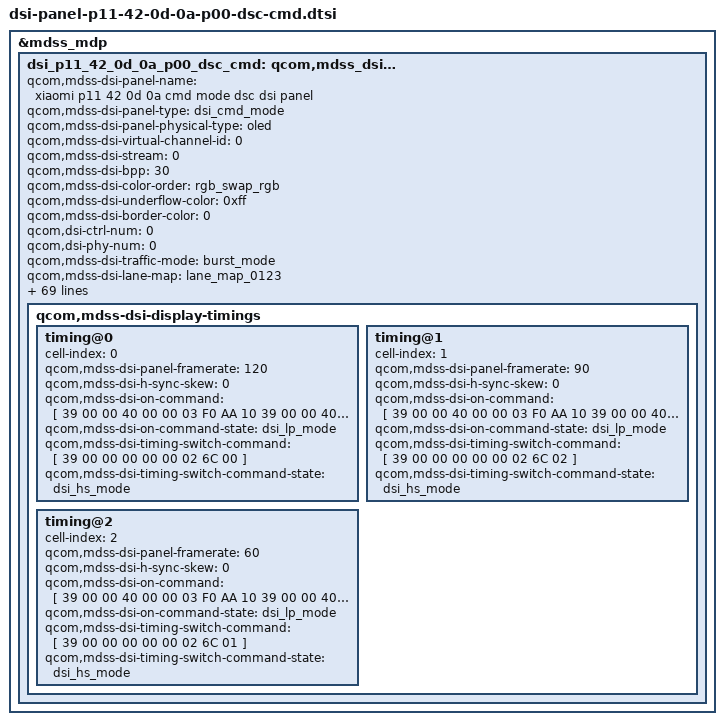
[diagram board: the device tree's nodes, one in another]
&mdss_mdp {
	dsi_p11_42_0d_0a_p00_dsc_cmd: qcom,mdss_dsi_p11_42_0d_0a_p00_dsc_cmd {
		qcom,mdss-dsi-panel-name = "xiaomi p11 42 0d 0a cmd mode dsc dsi panel";
		qcom,mdss-dsi-panel-type = "dsi_cmd_mode";
		qcom,mdss-dsi-panel-physical-type = "oled";
		qcom,mdss-dsi-virtual-channel-id = <0>;
		qcom,mdss-dsi-stream = <0>;
		qcom,mdss-dsi-bpp = <30>;
		qcom,mdss-dsi-color-order = "rgb_swap_rgb";
		qcom,mdss-dsi-underflow-color = <0xff>;
		qcom,mdss-dsi-border-color = <0>;
		qcom,dsi-ctrl-num = <0>;
		qcom,dsi-phy-num = <0>;
		qcom,mdss-dsi-traffic-mode = "burst_mode";
		qcom,mdss-dsi-lane-map = "lane_map_0123";
		qcom,mdss-dsi-bllp-eof-power-mode;
		qcom,mdss-dsi-bllp-power-mode;
		qcom,mdss-dsi-lane-0-state;
		qcom,mdss-dsi-lane-1-state;
		qcom,mdss-dsi-lane-2-state;
		qcom,mdss-dsi-lane-3-state;
		qcom,mdss-dsi-dma-trigger = "trigger_sw";
		qcom,mdss-dsi-mdp-trigger = "none";
		qcom,mdss-dsi-reset-sequence =<1 1>, <0 1>, <1 10>;
		qcom,mdss-pan-physical-width-dimension = <701>;
		qcom,mdss-pan-physical-height-dimension = <1521>;
		qcom,mdss-dsi-te-pin-select = <1>;
		qcom,mdss-dsi-wr-mem-start = <0x2c>;
		qcom,mdss-dsi-wr-mem-continue = <0x3c>;
		qcom,mdss-dsi-te-dcs-command = <1>;
		qcom,mdss-dsi-te-check-enable;
		qcom,mdss-dsi-te-using-te-pin;
		qcom,mdss-dsi-tx-eot-append;
		qcom,mdss-dsi-lp11-init;
		qcom,mdss-dsi-bl-inverted-dbv;
		qcom,mdss-dsi-panel-dimming-enabled;
		qcom,bl-update-flag = "delay_until_first_frame";
		qcom,mdss-dsi-panel-hdr-enabled;
		qcom,mdss-dsi-panel-hdr-color-primaries = <14500 15500 32000
			17000 15500 30000 8000 3000>;
		qcom,mdss-dsi-panel-peak-brightness = <32000000>;
		qcom,mdss-dsi-panel-blackness-level = <3230>;
		qcom,mdss-dsi-dma-schedule-line = <1>;
		qcom,mdss-dsi-dma-schedule-window = <50>;
		mi,panel-id = <0x00503131 0x50420D0A>;
		mi,panel-on-dimming-delay = <120>;

		/* IRQF_ONESHOT | IRQF_TRIGGER_HEIGH */
		//mi,esd-err-irq-gpio = <&tlmm 87 0x2004>;
		//mi,esd-err-irq-gpio-flag = <0x2004>;

		mi,mdss-dsi-panel-wp-read-command = [06 01 00 01 00 00 01 5C];
		mi,mdss-dsi-panel-wp-read-command-state = "dsi_hs_mode";
		mi,mdss-dsi-panel-wp-read-length = <8>;

		mi,mdss-dsi-panel-cell-id-read-command = [06 01 00 01 00 00 01 5A];
		mi,mdss-dsi-panel-cell-id-read-command-state = "dsi_hs_mode";
		mi,mdss-dsi-panel-cell-id-read-length = <14>;
		mi,max-brightness-clone = <16383>;
		mi,mdss-dsi-fac-bl-max-level = <13500>;
		mi,mdss-fac-brightness-max-level = <13500>;
		//mi,flatmode-status-check-enabled;
		//mi,mdss-dsi-panel-flatmode-status-command = [
		//		06 01 00 01 00 00 01 5F
		//];
		//mi,mdss-dsi-panel-flatmode-status-command-state = "dsi_hs_mode";
		//mi,mdss-dsi-panel-flatmode-status-read-length = <1>;
		//mi,mdss-dsi-panel-flatmode-on-status-value = <0x00>;

		mi,doze-hbm-dbv-level = <609>;
		mi,doze-lbm-dbv-level = <46>;
		mi,ddic-round-corner-enabled;
		qcom,mdss-disable-cesta-hw-sleep;

		qcom,mdss-dsi-display-timings {
			timing@0 {
				#include "dsi-panel-p11-42-0d-0a-p00-dsc-cmd-common.dtsi"
				cell-index = <0>;
				qcom,mdss-dsi-panel-framerate = <120>;
				qcom,mdss-dsi-h-sync-skew = <0>;

				qcom,mdss-dsi-on-command = [
					39 00 00 40 00 00 03 F0 AA 10
					39 00 00 40 00 00 02 65 04
					39 00 00 40 00 00 02 B0 02
					39 00 00 40 00 00 03 FF 5A 81
					39 00 00 40 00 00 02 65 03
					39 00 00 40 00 00 02 F3 04
					39 00 00 40 00 00 02 65 05
					39 00 00 40 00 00 02 F3 48
					39 00 00 40 00 00 02 03 01
					39 00 00 40 00 00 02 35 00
					39 00 00 40 00 00 02 53 20
					39 00 00 40 00 00 03 51 1F FF
					39 00 00 40 00 00 02 6F 02
					39 00 00 40 00 00 02 6C 00
					39 00 00 40 00 00 02 6D 00
					39 00 00 40 00 00 5F 70 11 00 00 89 30 80 09 CE 04 84 00 0A 02 42 02 42 02 00 02 22 00 20 00 F5 00 08 00 0C 0A AB 09 5A 18 00 10 D0 03 0C 20 00 06 0B 0B 33 0E 1C 2A 38 46 54 62 69 70 77 79 7B 7D 7E 01 02 01 00 09 40 09 BE 19 FC 19 FA 19 F8 1A 38 1A 78 1A B6 2A B6 2A F4 2A F4 4B 34 63 74 00 00 00 00 00 00
					39 00 00 40 00 00 02 72 00
					39 00 00 40 00 00 03 F0 AA 00
					39 00 00 40 00 00 03 FF 5A 00
					39 00 00 00 78 00 01 11
					39 00 00 00 00 00 01 29
		          ];
				qcom,mdss-dsi-on-command-state = "dsi_lp_mode";
				qcom,mdss-dsi-timing-switch-command = [
					//120hz
					39 00 00 00 00 00 02 6C 00
				];
				qcom,mdss-dsi-timing-switch-command-state = "dsi_hs_mode";
			};
			timing@1 {
				#include "dsi-panel-p11-42-0d-0a-dsc-cmd-common.dtsi"
				cell-index = <1>;
				qcom,mdss-dsi-panel-framerate = <90>;
				qcom,mdss-dsi-h-sync-skew = <0>;
				qcom,mdss-dsi-on-command = [
					39 00 00 40 00 00 03 F0 AA 10
					39 00 00 40 00 00 02 65 04
					39 00 00 40 00 00 02 B0 02
					39 00 00 40 00 00 03 FF 5A 81
					39 00 00 40 00 00 02 65 03
					39 00 00 40 00 00 02 F3 04
					39 00 00 40 00 00 02 65 05
					39 00 00 40 00 00 02 F3 48
					39 00 00 40 00 00 02 03 01
					39 00 00 40 00 00 02 35 00
					39 00 00 40 00 00 02 53 20
					39 00 00 40 00 00 03 51 1F FF
					39 00 00 40 00 00 02 6F 02
					39 00 00 40 00 00 02 6C 02
					39 00 00 40 00 00 02 6D 00
					39 00 00 40 00 00 5F 70 11 00 00 89 30 80 09 CE 04 84 00 0A 02 42 02 42 02 00 02 22 00 20 00 F5 00 08 00 0C 0A AB 09 5A 18 00 10 D0 03 0C 20 00 06 0B 0B 33 0E 1C 2A 38 46 54 62 69 70 77 79 7B 7D 7E 01 02 01 00 09 40 09 BE 19 FC 19 FA 19 F8 1A 38 1A 78 1A B6 2A B6 2A F4 2A F4 4B 34 63 74 00 00 00 00 00 00
					39 00 00 40 00 00 02 72 00
					39 00 00 40 00 00 03 F0 AA 00
					39 00 00 40 00 00 03 FF 5A 00
					39 00 00 00 78 00 01 11
					39 00 00 00 00 00 01 29
		        ];
				qcom,mdss-dsi-on-command-state = "dsi_lp_mode";
                 qcom,mdss-dsi-timing-switch-command = [
					//90hz
					39 00 00 00 00 00 02 6C 02
				];
				qcom,mdss-dsi-timing-switch-command-state = "dsi_hs_mode";
			};
			timing@2 {
				#include "dsi-panel-p11-42-0d-0a-p00-dsc-cmd-common.dtsi"
				cell-index = <2>;
				qcom,mdss-dsi-panel-framerate = <60>;
				qcom,mdss-dsi-h-sync-skew = <0>;
				qcom,mdss-dsi-on-command = [
					39 00 00 40 00 00 03 F0 AA 10
					39 00 00 40 00 00 02 65 04
					39 00 00 40 00 00 02 B0 02
					39 00 00 40 00 00 03 FF 5A 81
					39 00 00 40 00 00 02 65 03
					39 00 00 40 00 00 02 F3 04
					39 00 00 40 00 00 02 65 05
					39 00 00 40 00 00 02 F3 48
					39 00 00 40 00 00 02 03 01
					39 00 00 40 00 00 02 35 00
					39 00 00 40 00 00 02 53 20
					39 00 00 40 00 00 03 51 1F FF
					39 00 00 40 00 00 02 6F 02
					39 00 00 40 00 00 02 6C 01
					39 00 00 40 00 00 02 6D 00
					39 00 00 40 00 00 5F 70 11 00 00 89 30 80 09 CE 04 84 00 0A 02 42 02 42 02 00 02 22 00 20 00 F5 00 08 00 0C 0A AB 09 5A 18 00 10 D0 03 0C 20 00 06 0B 0B 33 0E 1C 2A 38 46 54 62 69 70 77 79 7B 7D 7E 01 02 01 00 09 40 09 BE 19 FC 19 FA 19 F8 1A 38 1A 78 1A B6 2A B6 2A F4 2A F4 4B 34 63 74 00 00 00 00 00 00
					39 00 00 40 00 00 02 72 00
					39 00 00 40 00 00 03 F0 AA 00
					39 00 00 40 00 00 03 FF 5A 00
					39 00 00 00 78 00 01 11
					39 00 00 00 00 00 01 29
		        ];
				qcom,mdss-dsi-on-command-state = "dsi_lp_mode";
                 qcom,mdss-dsi-timing-switch-command = [
					//60hz
					39 00 00 00 00 00 02 6C 01
				];
				qcom,mdss-dsi-timing-switch-command-state = "dsi_hs_mode";
			};
		};
	};
};

&dsi_p11_42_0d_0a_p00_dsc_cmd {
	qcom,panel-supply-entries = <&dsi_panel_pwr_supply_p11>;
	qcom,mdss-dsi-bl-pmic-control-type = "bl_ctrl_dcs";
	qcom,mdss-dsi-bl-min-level = <15>;
	qcom,mdss-dsi-bl-max-level = <16383>;
	qcom,bl-dsc-cmd-state = "dsi_hs_mode";
	qcom,mdss-brightness-max-level = <16383>;
	qcom,mdss-brightness-init-level = <614>;
	qcom,platform-reset-gpio = <&tlmm 98 0>;
	mi,panel-build-id-read-needed;
	mi,panel-build-id-read-length = <1>;
	mi,mdss-dsi-panel-build-id-read-command = [06 01 00 01 00 00 01 DA];
	mi,mdss-dsi-panel-build-id-read-command-state = "dsi_hs_mode";

	qcom,mdss-dsi-panel-vsync-delay;
	qcom,ulps-enabled;
	qcom,dsi-select-clocks = "pll_byte_clk0", "pll_dsi_clk0";
	qcom,mdss-dsi-clk-strength = <0x88>;
};
